# GD32F4xx register map
File version: 1.0
CPU: CM4 r2p1, little endian, MPU, FPU, 4 interrupt priority bits
Registers are 32-bit, read-write, reset 0x0 unless marked. A register's access mark holds for its fields unless they carry their own. Offsets are from the block's base; [hi:lo] are bit positions; {n}, {i} and the like mark numbered series.

## DBG — Debug support
Base 0xE0042000
0x00 ID ro — ID code register
  [31:0] ID_CODE — DBG ID code register
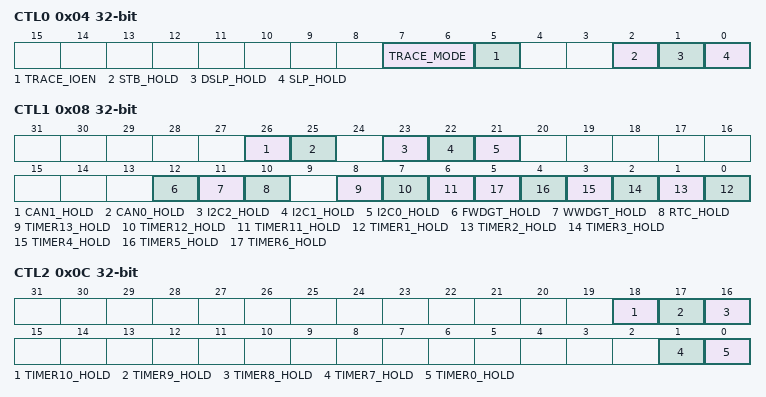
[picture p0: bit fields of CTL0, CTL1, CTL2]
0x04 CTL0 — Control register 0
  [7:6] TRACE_MODE — Trace pin allocation mode
  [5] TRACE_IOEN — Trace pin allocation enable
  [2] STB_HOLD — Standby mode hold register
  [1] DSLP_HOLD — Deep-sleep mode hold register
  [0] SLP_HOLD — Sleep mode hold register
0x08 CTL1 — Control register 1
  [26] CAN1_HOLD, [25] CAN0_HOLD, [23] I2C2_HOLD, [22] I2C1_HOLD, [21] I2C0_HOLD, [12] FWDGT_HOLD, [11] WWDGT_HOLD, [10] RTC_HOLD, [8] TIMER13_HOLD, [7] TIMER12_HOLD, [6] TIMER11_HOLD, [n-1] TIMER{n}_HOLD (n=1..6)
0x0C CTL2 — Control register 2
  [18] TIMER10_HOLD, [17] TIMER9_HOLD, [16] TIMER8_HOLD, [1] TIMER7_HOLD, [0] TIMER0_HOLD

## DCI — Digital Camera Interface
Base 0x50050000
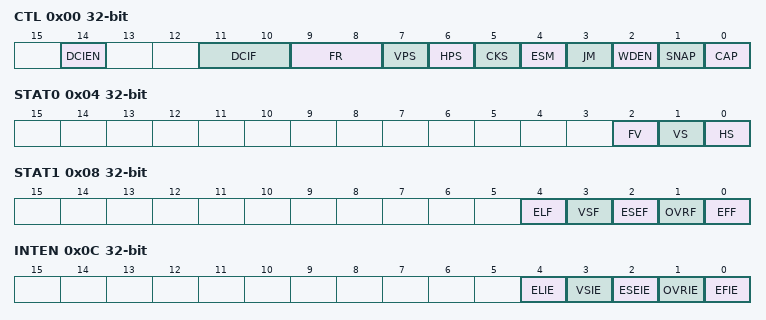
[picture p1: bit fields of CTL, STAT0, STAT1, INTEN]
0x00 CTL — Control register
  [14] DCIEN — DCI Enable
  [11:10] DCIF — Digital camera interface format
  [9:8] FR — Frame rate
  [7] VPS — Vertical Polarity Selection
  [6] HPS — Horizontal Polarity Selection
  [5] CKS — Clock Polarity Selection
  [4] ESM — Embedded Synchronous Mode
  [3] JM — JPEG mode
  [2] WDEN — Window Enable
  [1] SNAP — Snapshot mode
  [0] CAP — Capture Enable
0x04 STAT0 ro — Status register 0
  [2] FV — FIFO Valid
  [1] VS — VS line status
  [0] HS — HS line status
0x08 STAT1 ro — Status register 1
  [4] ELF — End of Line Flag
  [3] VSF — Vsync Flag
  [2] ESEF — Embedded Synchronous Error Flag
  [1] OVRF — FIFO Overrun Flag
  [0] EFF — End of Frame Flag
0x0C INTEN — Interrupt enable register
  [4] ELIE — End of Line Interrupt Enable
  [3] VSIE — Vsync Interrupt Enable
  [2] ESEIE — Embedded Synchronous Error Interrupt Enable
  [1] OVRIE — FIFO Overrun Interrupt Enable
  [0] EFIE — End of Frame Interrupt Enable
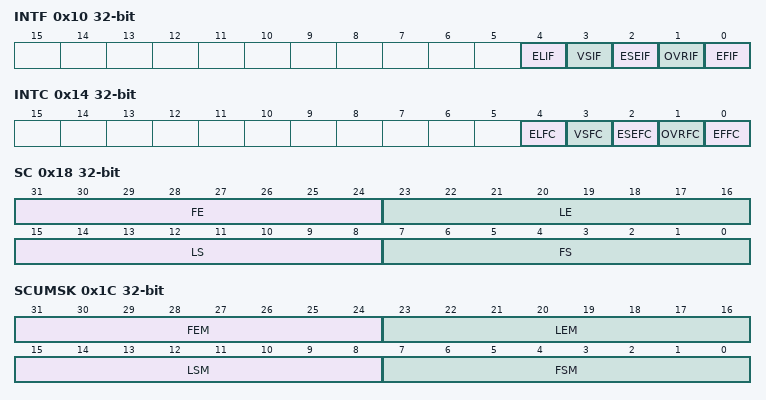
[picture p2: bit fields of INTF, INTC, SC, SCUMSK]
0x10 INTF ro — Interrupt flag register
  [4] ELIF — End of Line Interrupt Flag
  [3] VSIF — Vsync Interrupt Flag
  [2] ESEIF — Embedded Synchronous Error Interrupt Flag
  [1] OVRIF — FIFO Overrun Interrupt Flag
  [0] EFIF — End of Frame Interrupt Flag
0x14 INTC wo — Interrupt flag clear register
  [4] ELFC — End of Line Flag Clear
  [3] VSFC — Vsync flag clear
  [2] ESEFC — Clear embedded synchronous Error Flag
  [1] OVRFC — Clear FIFO Overrun Flag
  [0] EFFC — Clear End of Frame Flag
0x18 SC — Synchronization codes register
  [31:24] FE — Frame End Code in Embedded Synchronous Mode
  [23:16] LE — Line End Code in Embedded Synchronous Mode
  [15:8] LS — Line Start Code in Embedded Synchronous Mode
  [7:0] FS — Frame Start Code in Embedded Synchronous Mode
0x1C SCUMSK — Synchronization codes unmask register
  [31:24] FEM — Frame End Code unMask Bits in Embedded Synchronous Mode
  [23:16] LEM — Line End Code unMask Bits in Embedded Synchronous Mode
  [15:8] LSM — Line Start Code unMask Bits in Embedded Synchronous Mode
  [7:0] FSM — Frame Start Code unMask Bits in Embedded Synchronous Mode
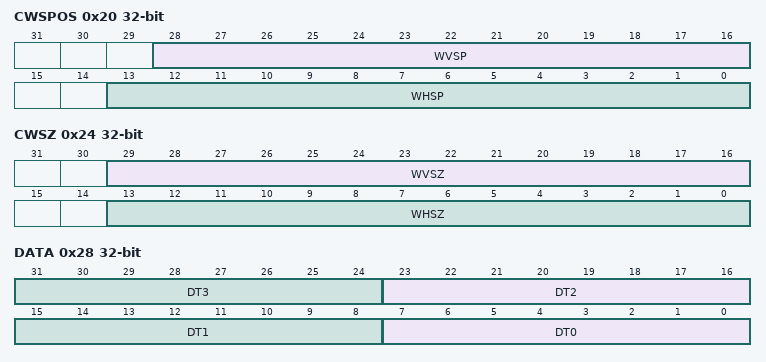
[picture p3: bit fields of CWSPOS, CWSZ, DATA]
0x20 CWSPOS — Cropping window start position register
  [28:16] WVSP — Window Vertical Start Position
  [13:0] WHSP — Window Horizontal Start Position
0x24 CWSZ — Cropping window size register
  [29:16] WVSZ — Window Vertical Size
  [13:0] WHSZ — Window Horizontal Size
0x28 DATA ro
  [8n+7:8n] DT{n} (n=0..3) — Pixel Data {n}

## ENET_MAC_FCTH — MAC flow control threshold register
Base 0x40029080
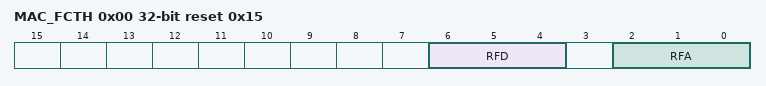
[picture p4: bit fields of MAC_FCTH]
0x00 MAC_FCTH reset 0x15 — Ethernet MAC flow control threshold register
  [6:4] RFD — Threshold of deactive flow control
  [2:0] RFA — Threshold of active flow control

## ENET_MSC — Ethernet: MAC statistics counters
Base 0x40028100
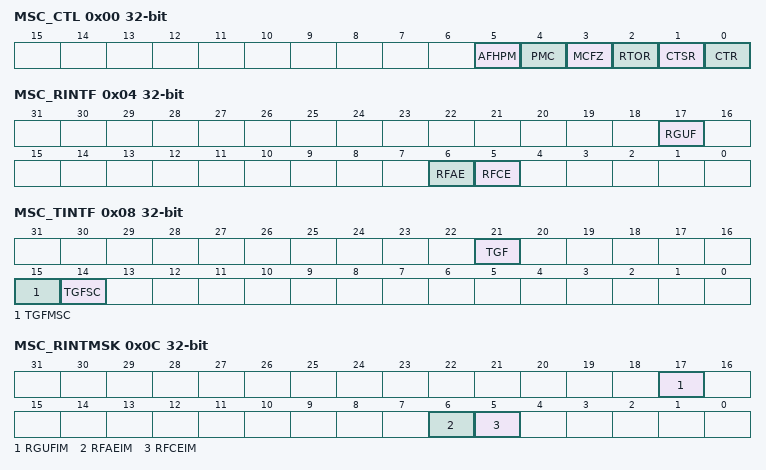
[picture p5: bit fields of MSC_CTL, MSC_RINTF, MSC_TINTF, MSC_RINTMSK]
0x00 MSC_CTL — Ethernet MSC control register (MSC_CTL)
  [5] AFHPM — Almost full or half preset mode
  [4] PMC wo — Preset MSC counter
  [3] MCFZ — MSC counter freeze
  [2] RTOR — Reset on read
  [1] CTSR — Counter stop rollover
  [0] CTR — Counter reset
0x04 MSC_RINTF ro — Ethernet MSC receive interrupt flag register (MSC_RINTF)
  [17] RGUF — Received Good Unicast Frames
  [6] RFAE — Received frames alignment error
  [5] RFCE — Received frames CRC error
0x08 MSC_TINTF ro — Ethernet MSC transmit interrupt flag register (MSC_TINTF)
  [21] TGF — Transmitted good frames
  [15] TGFMSC — Transmitted good frames more single collision
  [14] TGFSC — Transmitted good frames single collision
0x0C MSC_RINTMSK — Ethernet MSC receive interrupt mask register (MSC_RINTMSK)
  [17] RGUFIM — Received good unicast frames interrupt mask
  [6] RFAEIM — Received frames alignment error interrupt mask
  [5] RFCEIM — Received frame CRC error interrupt mask
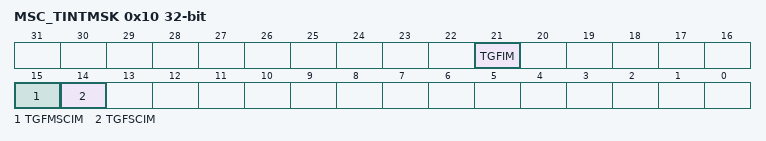
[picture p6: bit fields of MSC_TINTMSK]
0x10 MSC_TINTMSK — Ethernet MSC transmit interrupt mask register (MSC_TINTMSK)
  [21] TGFIM — Transmitted good frames interrupt mask
  [15] TGFMSCIM — Transmitted good frames more single interrupt collision mask
  [14] TGFSCIM — Transmitted good frames single collision interrupt mask
0x4C MSC_SCCNT ro — Ethernet MSC transmitted good frames after a single collision counter
  [31:0] SCC — Transmitted good frames after a single collision counter
0x50 MSC_MSCCNT ro — Ethernet MSC transmitted good frames after more than a single collision
  [31:0] MSCC — Transmitted good frames after more than a single collision counter
0x68 MSC_TGFCNT ro — Ethernet MSC transmitted good frames counter register
  [31:0] TGF — Transmitted good frames counter
0x94 MSC_RFCECNT ro — Ethernet MSC received frames with CRC error counter register
  [31:0] RFCER — Received frames with CRC error counter
0x98 MSC_RFAECNT ro — Ethernet MSC received frames with alignment error counter register
  [31:0] RFAER — Received frames with alignment error counter
0xC4 MSC_RGUFCNT ro — MSC received good unicast frames counter register
  [31:0] RGUF — Received good unicast frames counter
